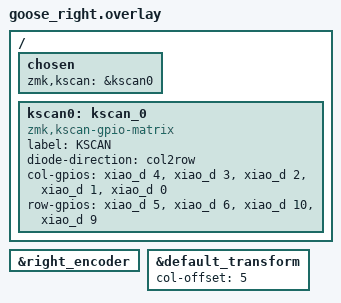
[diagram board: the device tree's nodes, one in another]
#include "goose.dtsi"

/ {
    chosen {
        zmk,kscan = &kscan0;
    };

    kscan0: kscan_0 {
        compatible = "zmk,kscan-gpio-matrix";
        label = "KSCAN";
        diode-direction = "col2row";


        col-gpios
            = <&xiao_d 4 GPIO_ACTIVE_HIGH>
            , <&xiao_d 3 GPIO_ACTIVE_HIGH>
            , <&xiao_d 2 GPIO_ACTIVE_HIGH>
            , <&xiao_d 1 GPIO_ACTIVE_HIGH>
            , <&xiao_d 0 GPIO_ACTIVE_HIGH>
            ;

        row-gpios
            = <&xiao_d 5 (GPIO_PULL_DOWN | GPIO_ACTIVE_HIGH)>
            , <&xiao_d 6 (GPIO_PULL_DOWN | GPIO_ACTIVE_HIGH)>
            , <&xiao_d 10 (GPIO_PULL_DOWN | GPIO_ACTIVE_HIGH)>
            , <&xiao_d 9 (GPIO_PULL_DOWN | GPIO_ACTIVE_HIGH)>
            ;
    };   

};

&right_encoder {
    status = "okay";
};

&default_transform {
    col-offset = <5>;
};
